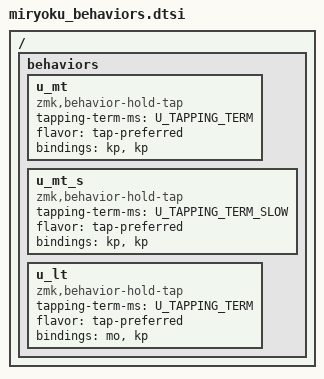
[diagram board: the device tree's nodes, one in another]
// Copyright 2022 Manna Harbour
// https://github.com/manna-harbour/miryoku

/ {
  behaviors {
    u_mt: u_mt {
      compatible = "zmk,behavior-hold-tap";
      #binding-cells = <2>;
      tapping-term-ms = <U_TAPPING_TERM>;
      flavor = "tap-preferred";
      bindings = <&kp>, <&kp>;
    };
    u_mt_s: u_mt_s {
      compatible = "zmk,behavior-hold-tap";
      #binding-cells = <2>;
      tapping-term-ms = <U_TAPPING_TERM_SLOW>;
      flavor = "tap-preferred";
      bindings = <&kp>, <&kp>;
    };
    u_lt: u_lt {
      compatible = "zmk,behavior-hold-tap";
      #binding-cells = <2>;
      tapping-term-ms = <U_TAPPING_TERM>;
      flavor = "tap-preferred";
      bindings = <&mo>, <&kp>;
    };
  };
};
